# SYSCTL_1.0 register map
Vendor: Texas Instruments
Peripheral module from a debugger description file (folder mspm0gx51x).
Registers are 32-bit, read-write, no defined reset value unless marked. A register's access mark holds for its fields unless they carry their own. Offsets are as the file gives them; lines under a group give offsets from that group; [hi:lo] are bit positions; {n}, {i} and the like mark numbered series; 'fields as' and 'values as' point back to an identical list; <NAME> marks a mode.

## SYSCTL (part 1 of 2)
0x800 SYSCTL_MGMT_ADC12B4MSPS0_PWREN — IP Enable Register
  [0] ENABLE — IP Enable
    0=Disable; 1=Enable
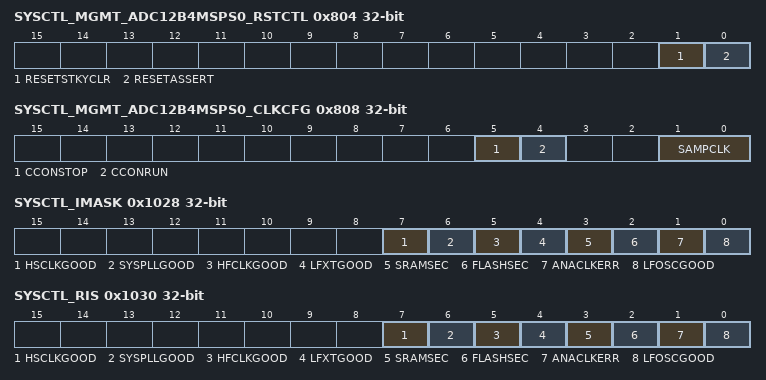
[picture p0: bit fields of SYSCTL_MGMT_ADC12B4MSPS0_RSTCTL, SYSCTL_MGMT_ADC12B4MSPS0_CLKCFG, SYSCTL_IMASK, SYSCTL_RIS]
0x804 SYSCTL_MGMT_ADC12B4MSPS0_RSTCTL — Power Control Register - Write Only Register, Always Read as 0
  [1] RESETSTKYCLR — Clear the RESET STICKY Bit
    1=Clear
  [0] RESETASSERT — Assert Reset to IP Domain.
    1=Do
0x808 SYSCTL_MGMT_ADC12B4MSPS0_CLKCFG — IP Clock Configuration Register
  [5] CCONSTOP — Conversion Clock is ON during STOP Mode
    0=Disable; 1=Enable
  [4] CCONRUN — Conversion Clock is ON during RUN Mode
    0=Disable; 1=Enable
  [1:0] SAMPCLK — Sample Window Clock
    0=ULPCLK; 1=SYSOSC; 2=HFCLK
0x814 SYSCTL_MGMT_ADC12B4MSPS0_STAT ro — IP State Register - Read Only
  [16] RESETSTKY — IP has been Reset
    0=clear; 1=Set
0x1020 SYSCTL_IIDX ro — SYSCTL interrupt index
  [3:0] STAT — The SYSCTL interrupt index (IIDX) register generates a value corresponding to the highest priority pending interrupt source. This value may be used as an address offset for fast, deterministic handling in the interrupt service routine. A read of the IIDX register will clear the corresponding interrupt status in the RIS and MIS registers.
    0=NO_INTR (No interrupt pending); 1=LFOSCGOOD (LFOSCGOOD interrupt pending); 2=ANACLKERR; 3=FLASHSEC; 4=SRAMSEC; 5=LFXTGOOD; 6=HFCLKGOOD; 7=SYSPLLGOOD; 8=HSCLKGOOD
0x1028 SYSCTL_IMASK — SYSCTL interrupt mask
  [7] HSCLKGOOD
    0=DISABLE; 1=ENABLE
  [6] SYSPLLGOOD
    0=DISABLE; 1=ENABLE
  [5] HFCLKGOOD
    0=DISABLE; 1=ENABLE
  [4] LFXTGOOD
    0=DISABLE; 1=ENABLE
  [3] SRAMSEC — SRAM Single Error Correct
    0=DISABLE; 1=ENABLE
  [2] FLASHSEC — Flash Single Error Correct
    0=DISABLE; 1=ENABLE
  [1] ANACLKERR — Analog Clocking Consistency Error
    0=DISABLE; 1=ENABLE
  [0] LFOSCGOOD — Enable or disable the LFOSCGOOD interrupt. LFOSCGOOD indicates that the LFOSC has started successfully.
    0=DISABLE (Interrupt disabled); 1=ENABLE (Interrupt enabled)
0x1030 SYSCTL_RIS ro — SYSCTL raw interrupt status
  [7] HSCLKGOOD
    0=FALSE; 1=TRUE
  [6] SYSPLLGOOD
    0=FALSE; 1=TRUE
  [5] HFCLKGOOD
    0=FALSE; 1=TRUE
  [4] LFXTGOOD
    0=FALSE; 1=TRUE
  [3] SRAMSEC — SRAM Single Error Correct
    0=FALSE; 1=TRUE
  [2] FLASHSEC — Flash Single Error Correct
    0=FALSE; 1=TRUE
  [1] ANACLKERR — Analog Clocking Consistency Error
    0=FALSE; 1=TRUE
  [0] LFOSCGOOD — Raw status of the LFOSCGOOD interrupt.
    0=FALSE (No interrupt pending); 1=TRUE (Interrupt pending)
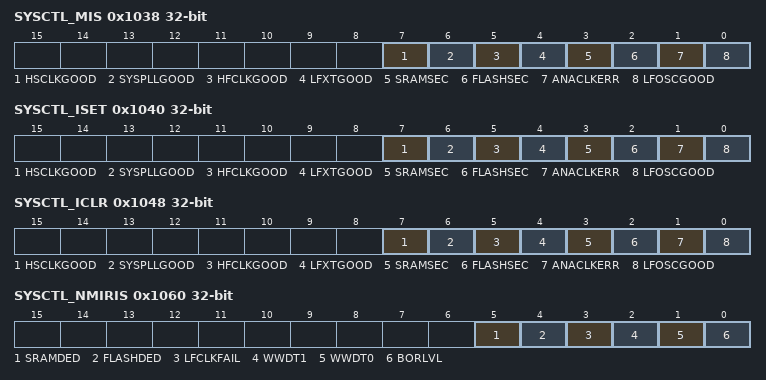
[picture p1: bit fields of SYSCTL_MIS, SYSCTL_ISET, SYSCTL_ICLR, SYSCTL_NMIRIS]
0x1038 SYSCTL_MIS ro — SYSCTL masked interrupt status
  [7] HSCLKGOOD
    0=FALSE; 1=TRUE
  [6] SYSPLLGOOD
    0=FALSE; 1=TRUE
  [5] HFCLKGOOD
    0=FALSE; 1=TRUE
  [4] LFXTGOOD
    0=FALSE; 1=TRUE
  [3] SRAMSEC — SRAM Single Error Correct
    0=FALSE; 1=TRUE
  [2] FLASHSEC — Flash Single Error Correct
    0=FALSE; 1=TRUE
  [1] ANACLKERR — Analog Clocking Consistency Error
    0=FALSE; 1=TRUE
  [0] LFOSCGOOD — Masked status of the LFOSCGOOD interrupt.
    0=FALSE (No interrupt pending); 1=TRUE (Interrupt pending)
0x1040 SYSCTL_ISET — SYSCTL interrupt set
  [7] HSCLKGOOD
    0=NO_EFFECT; 1=SET
  [6] SYSPLLGOOD
    0=NO_EFFECT; 1=SET
  [5] HFCLKGOOD
    0=NO_EFFECT; 1=SET
  [4] LFXTGOOD
    0=NO_EFFECT; 1=SET
  [3] SRAMSEC — SRAM Single Error Correct
    0=NO_EFFECT; 1=SET
  [2] FLASHSEC — Flash Single Error Correct
    0=NO_EFFECT; 1=SET
  [1] ANACLKERR — Analog Clocking Consistency Error
    0=NO_EFFECT; 1=SET
  [0] LFOSCGOOD — Set the LFOSCGOOD interrupt.
    0=NO_EFFECT (Writing 0h hs no effect); 1=SET (Set interrupt)
0x1048 SYSCTL_ICLR — SYSCTL interrupt clear
  [7] HSCLKGOOD
    0=NO_EFFECT; 1=CLR
  [6] SYSPLLGOOD
    0=NO_EFFECT; 1=CLR
  [5] HFCLKGOOD
    0=NO_EFFECT; 1=CLR
  [4] LFXTGOOD
    0=NO_EFFECT; 1=CLR
  [3] SRAMSEC — SRAM Single Error Correct
    0=NO_EFFECT; 1=CLR
  [2] FLASHSEC — Flash Single Error Correct
    0=NO_EFFECT; 1=CLR
  [1] ANACLKERR — Analog Clocking Consistency Error
    0=NO_EFFECT; 1=CLR
  [0] LFOSCGOOD — Clear the LFOSCGOOD interrupt.
    0=NO_EFFECT (Writing 0h has no effect); 1=CLR (Clear interrupt)
0x1050 SYSCTL_NMIIIDX ro — NMI interrupt index
  [3:0] STAT — The NMI interrupt index (NMIIIDX) register generates a value corresponding to the highest priority pending NMI source. This value may be used as an address offset for fast, deterministic handling in the NMI service routine. A read of the NMIIIDX register will clear the corresponding interrupt status in the NMIRIS register.
    0=NO_INTR (No NMI pending); 1=BORLVL (BOR Threshold NMI pending); 2=WWDT0; 3=WWDT1; 4=LFCLKFAIL; 5=FLASHDED; 6=SRAMDED
0x1060 SYSCTL_NMIRIS ro — NMI raw interrupt status
  [5] SRAMDED — SRAM Double Error Detect
    0=FALSE; 1=TRUE
  [4] FLASHDED — Flash Double Error Detect
    0=FALSE; 1=TRUE
  [3] LFCLKFAIL — LFXT-EXLF Monitor Fail
    0=FALSE; 1=TRUE
  [2] WWDT1 — Watch Dog 0 Fault
    0=FALSE; 1=TRUE
  [1] WWDT0 — Watch Dog 0 Fault
    0=FALSE; 1=TRUE
  [0] BORLVL — Raw status of the BORLVL NMI
    0=FALSE (No interrupt pending); 1=TRUE (Interrupt pending)
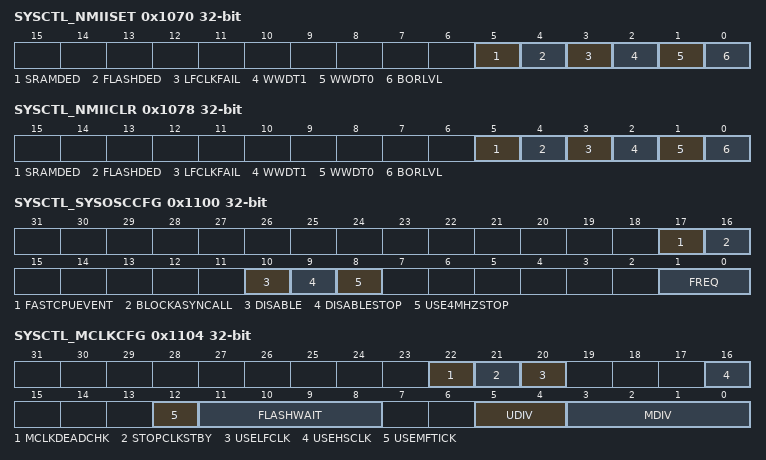
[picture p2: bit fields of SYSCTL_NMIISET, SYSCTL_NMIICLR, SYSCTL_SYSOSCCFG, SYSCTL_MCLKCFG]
0x1070 SYSCTL_NMIISET — NMI interrupt set
  [5] SRAMDED — SRAM Double Error Detect
    0=NO_EFFECT; 1=SET
  [4] FLASHDED — Flash Double Error Detect
    0=NO_EFFECT; 1=SET
  [3] LFCLKFAIL — LFXT-EXLF Monitor Fail
    0=NO_EFFECT; 1=SET
  [2] WWDT1 — Watch Dog 0 Fault
    0=NO_EFFECT; 1=SET
  [1] WWDT0 — Watch Dog 0 Fault
    0=NO_EFFECT; 1=SET
  [0] BORLVL — Set the BORLVL NMI
    0=NO_EFFECT (Writing 0h hs no effect); 1=SET (Set interrupt)
0x1078 SYSCTL_NMIICLR — NMI interrupt clear
  [5] SRAMDED — SRAM Double Error Detect
    0=NO_EFFECT; 1=CLR
  [4] FLASHDED — Flash Double Error Detect
    0=NO_EFFECT; 1=CLR
  [3] LFCLKFAIL — LFXT-EXLF Monitor Fail
    0=NO_EFFECT; 1=CLR
  [2] WWDT1 — Watch Dog 0 Fault
    0=NO_EFFECT; 1=CLR
  [1] WWDT0 — Watch Dog 0 Fault
    0=NO_EFFECT; 1=CLR
  [0] BORLVL — Clr the BORLVL NMI
    0=NO_EFFECT (Writing 0h hs no effect); 1=CLR (Clear interrupt)
0x1100 SYSCTL_SYSOSCCFG — SYSOSC configuration
  [17] FASTCPUEVENT — FASTCPUEVENT may be used to assert a fast clock request when an interrupt is asserted to the CPU, reducing interrupt latency.
    0=DISABLE (An interrupt to the CPU will not assert a fast clock request); 1=ENABLE (An interrupt to the CPU will assert a fast clock request)
  [16] BLOCKASYNCALL — BLOCKASYNCALL may be used to mask block all asynchronous fast clock requests, preventing hardware from dynamically changing the active clock configuration when operating in a given mode.
    0=DISABLE (Asynchronous fast clock requests are controlled by the requesting peripheral); 1=ENABLE (All asynchronous fast clock requests are blocked)
  [10] DISABLE — DISABLE sets the SYSOSC enable/disable policy. SYSOSC may be powered off in RUN, SLEEP, and STOP modes to reduce power consumption. When SYSOSC is disabled, MCLK and ULPCLK are sourced from LFCLK.
    0=DISABLE (Do not disable SYSOSC); 1=ENABLE (Disable SYSOSC immediately and source MCLK and ULPCLK from LFCLK)
  [9] DISABLESTOP — DISABLESTOP sets the SYSOSC stop mode enable/disable policy. When operating in STOP mode, the SYSOSC may be automatically disabled. When set, ULPCLK will run from LFCLK in STOP mode and SYSOSC will be disabled to reduce power consumption.
    0=DISABLE (Do not disable SYSOSC in STOP mode); 1=ENABLE (Disable SYSOSC in STOP mode and source ULPCLK from LFCLK)
  [8] USE4MHZSTOP — USE4MHZSTOP sets the SYSOSC stop mode frequency policy. When entering STOP mode, the SYSOSC frequency may be automatically switched to 4MHz to reduce SYSOSC power consumption.
    0=DISABLE (Do not gear shift the SYSOSC to 4MHz in STOP mode); 1=ENABLE (Gear shift SYSOSC to 4MHz in STOP mode)
  [1:0] FREQ — Target operating frequency for the system oscillator (SYSOSC)
    0=SYSOSCBASE (Base frequency (32MHz)); 1=SYSOSC4M (Low frequency (4MHz)); 2=SYSOSCUSER (User-trimmed frequency (16 or 24 MHz))
0x1104 SYSCTL_MCLKCFG — Main clock (MCLK) configuration
  [22] MCLKDEADCHK — MCLKDEADCHK enables or disables the continuous MCLK dead check monitor. LFCLK must be running before MCLKDEADCHK is enabled.
    0=DISABLE (The MCLK dead check monitor is disabled); 1=ENABLE (The MCLK dead check monitor is enabled)
  [21] STOPCLKSTBY — STOPCLKSTBY sets the STANDBY mode policy (STANDBY0 or STANDBY1). When set, ULPCLK and LFCLK are disabled to all peripherals in STANDBY mode, with the exception of TIMG0 and TIMG1 which continue to run. Wake-up is only possible via an asynchronous fast clock request.
    0=DISABLE (ULPCLK/LFCLK runs to all PD0 peripherals in STANDBY mode); 1=ENABLE (ULPCLK/LFCLK is disabled to all peripherals in STANDBY mode except TIMG0 and TIMG1)
  [20] USELFCLK — USELFCLK sets the MCLK source policy. Set USELFCLK to use LFCLK as the MCLK source. Note that setting USELFCLK does not disable SYSOSC, and SYSOSC remains available for direct use by analog modules.
    0=DISABLE (MCLK will not use the low frequency clock (LFCLK)); 1=ENABLE (MCLK will use the low frequency clock (LFCLK))
  [16] USEHSCLK — USEHSCLK, together with USELFCLK, sets the MCLK source policy. Set USEHSCLK to use HSCLK (HFCLK or SYSPLL) as the MCLK source in RUN and SLEEP modes.
    0=DISABLE (MCLK will not use the high speed clock (HSCLK)); 1=ENABLE (MCLK will use the high speed clock (HSCLK) in RUN and SLEEP mode)
  [12] USEMFTICK — USEMFTICK specifies whether the 4MHz constant-rate clock (MFCLK) to peripherals is enabled or disabled. When enabled, MDIV must be disabled (set to 0h=/1).
    0=DISABLE (The 4MHz rate MFCLK to peripherals is enabled); 1=ENABLE (The 4MHz rate MFCLK to peripherals is enabled.)
  [11:8] FLASHWAIT — FLASHWAIT specifies the number of flash wait states when MCLK is sourced from HSCLK. FLASHWAIT has no effect when MCLK is sourced from SYSOSC or LFCLK.
    0=WAIT0 (No flash wait states are applied); 1=WAIT1 (One flash wait state is applied); 2=WAIT2 (2 flash wait states are applied)
  [5:4] UDIV — UDIV specifies the ULPCLK divider when MCLK is sourced from HSCLK. UDIV has no effect when MCLK is sourced from SYSOSC or LFCLK.
    0=NODIVIDE (ULPCLK is not divided and is equal to MCLK); 1=DIVIDE2 (ULPCLK is MCLK/2 (divided-by-2))
  [3:0] MDIV — MDIV may be used to divide the MCLK frequency when MCLK is sourced from SYSOSC. MDIV=0h corresponds to /1 (no divider). MDIV=1h corresponds to /2 (divide-by-2). MDIV=Fh corresponds to /16 (divide-by-16). MDIV may be set between /1 and /16 on an integer basis.
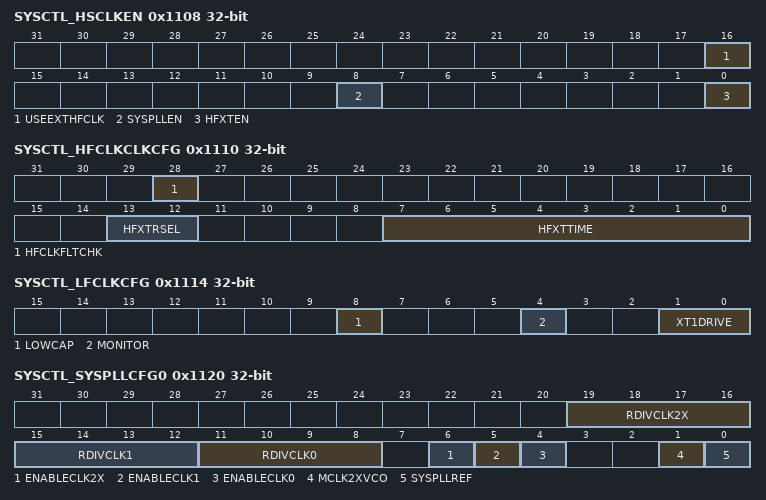
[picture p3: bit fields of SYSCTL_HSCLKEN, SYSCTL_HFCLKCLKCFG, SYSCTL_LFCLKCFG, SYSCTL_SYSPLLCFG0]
0x1108 SYSCTL_HSCLKEN — High-speed clock (HSCLK) source enable/disable
  [16] USEEXTHFCLK — USEEXTHFCLK selects the HFCLK_IN digital clock input to be the source for HFCLK. When disabled, HFXT is the HFCLK source and HFXTEN may be set. Do not set HFXTEN and USEEXTHFCLK simultaneously.
    0=DISABLE (Use HFXT as the HFCLK source); 1=ENABLE (Use the HFCLK_IN digital clock input as the HFCLK source)
  [8] SYSPLLEN — SYSPLLEN enables or disables the system phase-lock loop (SYSPLL).
    0=DISABLE (Disable the SYSPLL); 1=ENABLE (Enable the SYSPLL)
  [0] HFXTEN — HFXTEN enables or disables the high frequency crystal oscillator (HFXT).
    0=DISABLE (Disable the HFXT); 1=ENABLE (Enable the HFXT)
0x110C SYSCTL_HSCLKCFG — High-speed clock (HSCLK) source selection
  [0] HSCLKSEL — HSCLKSEL selects the HSCLK source (SYSPLL or HFCLK).
    0=SYSPLL (HSCLK is sourced from the SYSPLL); 1=HFCLKCLK (HSCLK is sourced from the HFCLK)
0x1110 SYSCTL_HFCLKCLKCFG — High-frequency clock (HFCLK) configuration
  [28] HFCLKFLTCHK — HFCLKFLTCHK enables or disables the HFCLK startup monitor.
    0=DISABLE (HFCLK startup is not checked); 1=ENABLE (HFCLK startup is checked)
  [13:12] HFXTRSEL — HFXT Range Select
    0=RANGE4TO8 (4MHz <= HFXT frequency <= 8MHz); 1=RANGE8TO16 (8MHz < HFXT frequency <= 16MHz); 2=RANGE16TO32 (16MHz < HFXT frequency <= 32MHz); 3=RANGE32TO48 (32MHz < HFXT frequency <= 48MHz)
  [7:0] HFXTTIME — HFXTTIME specifies the HFXT startup time in 64us resolution. If the HFCLK startup monitor is enabled (HFCLKFLTCHK), HFXT will be checked after this time expires.
    0=MINSTARTTIME (Minimum startup time (approximatly zero)); 255=MAXSTARTTIME (Maximum startup time (approximatly 16.32ms))
0x1114 SYSCTL_LFCLKCFG — Low frequency crystal oscillator (LFXT) configuration
  [8] LOWCAP — LOWCAP controls the low-power LFXT mode. When the LFXT load capacitance is less than 3pf, LOWCAP may be set for reduced power consumption.
    0=DISABLE (LFXT low capacitance mode is disabled); 1=ENABLE (LFXT low capacitance mode is enabled)
  [4] MONITOR — MONITOR enables or disables the LFCLK monitor, which continuously checks LFXT or LFCLK_IN for a clock stuck fault.
    0=DISABLE (Clock monitor is disabled); 1=ENABLE (Clock monitor is enabled)
  [1:0] XT1DRIVE — XT1DRIVE selects the low frequency crystal oscillator (LFXT) drive strength.
    0=LOWESTDRV (Lowest drive and current); 1=LOWERDRV (Lower drive and current); 2=HIGHERDRV (Higher drive and current); 3=HIGHESTDRV (Highest drive and current)
0x1120 SYSCTL_SYSPLLCFG0 — SYSPLL reference and output configuration
  [19:16] RDIVCLK2X — RDIVCLK2X sets the final divider for the SYSPLLCLK2X output.
    {v}=CLK2XDIV{v+1} (SYSPLLCLK1 is divided by {v+1}) (v=0..15)
  [15:12] RDIVCLK1 — RDIVCLK1 sets the final divider for the SYSPLLCLK1 output.
    0=CLK1DIV2 (SYSPLLCLK1 is divided by 2); 1=CLK1DIV4 (SYSPLLCLK1 is divided by 4); 2=CLK1DIV6 (SYSPLLCLK1 is divided by 6); 3=CLK1DIV8 (SYSPLLCLK1 is divided by 8); 4=CLK1DIV10 (SYSPLLCLK1 is divided by 10); 5=CLK1DIV12 (SYSPLLCLK1 is divided by 12); 6=CLK1DIV14 (SYSPLLCLK1 is divided by 14); 7=CLK1DIV16 (SYSPLLCLK1 is divided by 16); 8=CLK1DIV18 (SYSPLLCLK1 is divided by 18); 9=CLK1DIV20 (SYSPLLCLK1 is divided by 20); 10=CLK1DIV22 (SYSPLLCLK1 is divided by 22); 11=CLK1DIV24 (SYSPLLCLK1 is divided by 24); 12=CLK1DIV26 (SYSPLLCLK1 is divided by 26); 13=CLK1DIV28 (SYSPLLCLK1 is divided by 28); 14=CLK1DIV30 (SYSPLLCLK1 is divided by 30); 15=CLK1DIV32 (SYSPLLCLK1 is divided by 32)
  [11:8] RDIVCLK0 — RDIVCLK0 sets the final divider for the SYSPLLCLK0 output.
    0=CLK0DIV2 (SYSPLLCLK0 is divided by 2); 1=CLK0DIV4 (SYSPLLCLK0 is divided by 4); 2=CLK0DIV6 (SYSPLLCLK0 is divided by 6); 3=CLK0DIV8 (SYSPLLCLK0 is divided by 8); 4=CLK0DIV10 (SYSPLLCLK0 is divided by 10); 5=CLK0DIV12 (SYSPLLCLK0 is divided by 12); 6=CLK0DIV14 (SYSPLLCLK0 is divided by 14); 7=CLK0DIV16 (SYSPLLCLK0 is divided by 16); 8=CLK0DIV18 (SYSPLLCLK0 is divided by 18); 9=CLK0DIV20 (SYSPLLCLK0 is divided by 20); 10=CLK0DIV22 (SYSPLLCLK0 is divided by 22); 11=CLK0DIV24 (SYSPLLCLK0 is divided by 24); 12=CLK0DIV26 (SYSPLLCLK0 is divided by 26); 13=CLK0DIV28 (SYSPLLCLK0 is divided by 28); 14=CLK0DIV30 (SYSPLLCLK0 is divided by 30); 15=CLK0DIV32 (SYSPLLCLK0 is divided by 32)
  [6] ENABLECLK2X — ENABLECLK2X enables or disables the SYSPLLCLK2X output.
    0=DISABLE (SYSPLLCLK2X is disabled); 1=ENABLE (SYSPLLCLK2X is enabled)
  [5] ENABLECLK1 — ENABLECLK1 enables or disables the SYSPLLCLK1 output.
    0=DISABLE (SYSPLLCLK1 is disabled); 1=ENABLE (SYSPLLCLK1 is enabled)
  [4] ENABLECLK0 — ENABLECLK0 enables or disables the SYSPLLCLK0 output.
    0=DISABLE (SYSPLLCLK0 is disabled); 1=ENABLE (SYSPLLCLK0 is enabled)
  [1] MCLK2XVCO — MCLK2XVCO selects the SYSPLL output which is sent to the HSCLK mux for use by MCLK.
    0=DISABLE (The SYSPLLCLK0 output is sent to the HSCLK mux); 1=ENABLE (The SYSPLLCLK2X output is sent to the HSCLK mux)
  [0] SYSPLLREF — SYSPLLREF selects the system PLL (SYSPLL) reference clock source.
    0=SYSOSC (SYSPLL reference is SYSOSC); 1=HFCLK (SYSPLL reference is HFCLK)
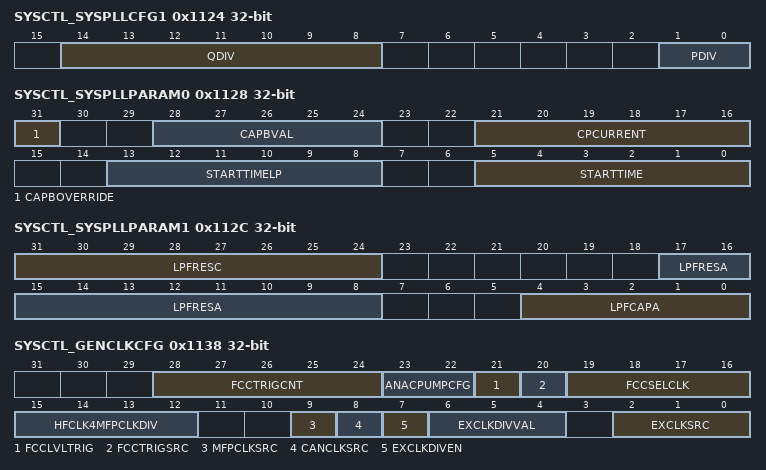
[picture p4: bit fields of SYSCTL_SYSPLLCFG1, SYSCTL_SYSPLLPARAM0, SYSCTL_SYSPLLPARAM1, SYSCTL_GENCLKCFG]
0x1124 SYSCTL_SYSPLLCFG1 — SYSPLL reference and feedback divider
  [14:8] QDIV — QDIV selects the SYSPLL feedback path divider.
    0=INVALID (Divide-by-one is not a valid QDIV option); 1=QDIVMIN (Feedback path is divided by 2); 126=QDIVMAX (Feedback path is divided by 127 (0x7E))
  [1:0] PDIV — PDIV selects the SYSPLL reference clock prescale divider.
    0=REFDIV1 (SYSPLLREF is not divided); 1=REFDIV2 (SYSPLLREF is divided by 2); 2=REFDIV4 (SYSPLLREF is divided by 4); 3=REFDIV8 (SYSPLLREF is divided by 8)
0x1128 SYSCTL_SYSPLLPARAM0 — SYSPLL PARAM0 (load from FACTORY region)
  [31] CAPBOVERRIDE — CAPBOVERRIDE controls the override for Cap B
    0=DISABLE (Cap B override disabled); 1=ENABLE (Cap B override enabled)
  [28:24] CAPBVAL — Override value for Cap B
  [21:16] CPCURRENT — Charge pump current
  [13:8] STARTTIMELP — Startup time from low power mode exit to locked clock, in 1us resolution
  [5:0] STARTTIME — Startup time from enable to locked clock, in 1us resolution
0x112C SYSCTL_SYSPLLPARAM1 — SYSPLL PARAM1 (load from FACTORY region)
  [31:24] LPFRESC — Loop filter Res C
  [17:8] LPFRESA — Loop filter Res A
  [4:0] LPFCAPA — Loop filter Cap A
0x1138 SYSCTL_GENCLKCFG — General clock configuration
  [28:24] FCCTRIGCNT — FCCTRIGCNT specifies the number of trigger clock periods in the trigger window. FCCTRIGCNT=0h (one trigger clock period) up to 1Fh (32 trigger clock periods) may be specified.
  [23:22] ANACPUMPCFG — ANACPUMPCFG selects the analog mux charge pump (VBOOST) enable method.
    0=ONDEMAND (VBOOST is enabled on request from a COMP, GPAMP, or OPA); 1=ONACTIVE (VBOOST is enabled when the device is in RUN or SLEEP mode, or when a COMP/GPAMP/OPA is enabled); 2=ONALWAYS (VBOOST is always enabled)
  [21] FCCLVLTRIG — FCCLVLTRIG selects the frequency clock counter (FCC) trigger mode.
    0=RISE2RISE (Rising edge to rising edge triggered); 1=LEVEL (Level triggered)
  [20] FCCTRIGSRC — FCCTRIGSRC selects the frequency clock counter (FCC) trigger source.
    0=EXTPIN (FCC trigger is the external pin); 1=LFCLK (FCC trigger is the LFCLK)
  [19:16] FCCSELCLK — FCCSELCLK selectes the frequency clock counter (FCC) clock source.
    0=MCLK (FCC clock is MCLK); 1=SYSOSC (FCC clock is SYSOSC); 2=HFCLK (FCC clock is HFCLK); 3=EXTCLK (FCC clock is the CLK_OUT selection); 4=SYSPLLCLK0 (FCC clock is SYSPLLCLK0); 5=SYSPLLCLK1 (FCC clock is SYSPLLCLK1); 6=SYSPLLCLK2X (FCC clock is SYSPLLCLK2X); 7=FCCIN (FCC clock is the FCCIN external input)
  [15:12] HFCLK4MFPCLKDIV — HFCLK4MFPCLKDIV selects the divider applied to HFCLK when HFCLK is used as the MFPCLK source. Integer dividers from /1 to /16 may be selected.
    0=DIV1 (HFCLK is not divided before being used for MFPCLK); {v}=DIV{v+1} (HFCLK is divided by {v+1} before being used for MFPCLK) (v=1..15)
  [9] MFPCLKSRC — MFPCLKSRC selects the MFPCLK (middle frequency precision clock) source.
    0=SYSOSC (MFPCLK is sourced from SYSOSC); 1=HFCLK (MFPCLK is sourced from HFCLK)
  [8] CANCLKSRC — CANCLKSRC selects the CANCLK source.
    0=HFCLK (CANCLK source is HFCLK); 1=SYSPLLOUT1 (CANCLK source is SYSPLLCLK1)
  [7] EXCLKDIVEN — EXCLKDIVEN enables or disables the divider function of the CLK_OUT external clock output block.
    0=PASSTHRU (CLock divider is disabled (passthrough, EXCLKDIVVAL is not applied)); 1=ENABLE (Clock divider is enabled (EXCLKDIVVAL is applied))
  [6:4] EXCLKDIVVAL — EXCLKDIVVAL selects the divider value for the divider in the CLK_OUT external clock output block.
    0=DIV2 (CLK_OUT source is divided by 2); 1=DIV4 (CLK_OUT source is divided by 4); 2=DIV6 (CLK_OUT source is divided by 6); 3=DIV8 (CLK_OUT source is divided by 8); 4=DIV10 (CLK_OUT source is divided by 10); 5=DIV12 (CLK_OUT source is divided by 12); 6=DIV14 (CLK_OUT source is divided by 14); 7=DIV16 (CLK_OUT source is divided by 16)
  [2:0] EXCLKSRC — EXCLKSRC selects the source for the CLK_OUT external clock output block. ULPCLK and MFPCLK require the CLK_OUT divider (EXCLKDIVEN) to be enabled
    0=SYSOSC (CLK_OUT is SYSOSC); 1=ULPCLK (CLK_OUT is ULPCLK (EXCLKDIVEN must be enabled)); 2=LFCLK (CLK_OUT is LFCLK); 3=MFPCLK (CLK_OUT is MFPCLK (EXCLKDIVEN must be enabled)); 4=HFCLK (CLK_OUT is HFCLK); 5=SYSPLLOUT1 (CLK_OUT is SYSPLLCLK1 (SYSPLLCLK1 must be <=48MHz))
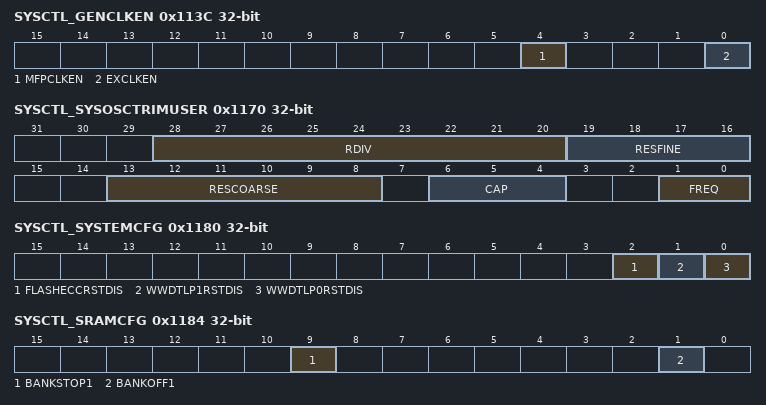
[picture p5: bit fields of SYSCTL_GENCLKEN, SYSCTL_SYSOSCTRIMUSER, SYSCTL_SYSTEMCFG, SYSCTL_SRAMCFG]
0x113C SYSCTL_GENCLKEN — General clock enable control
  [4] MFPCLKEN — MFPCLKEN enables the middle frequency precision clock (MFPCLK).
    0=DISABLE (MFPCLK is disabled); 1=ENABLE (MFPCLK is enabled)
  [0] EXCLKEN — EXCLKEN enables the CLK_OUT external clock output block.
    0=DISABLE (CLK_OUT block is disabled); 1=ENABLE (CLK_OUT block is enabled)
0x1140 SYSCTL_PMODECFG — Power mode configuration
  [1:0] DSLEEP — DSLEEP selects the operating mode to enter upon a DEEPSLEEP request from the CPU.
    0=STOP (STOP mode is entered); 1=STANDBY (STANDBY mode is entered); 2=SHUTDOWN (SHUTDOWN mode is entered)
0x1150 SYSCTL_FCC ro — Frequency clock counter (FCC) count
  [21:0] DATA — Frequency clock counter (FCC) count value.
0x1170 SYSCTL_SYSOSCTRIMUSER — SYSOSC user-specified trim
  [28:20] RDIV — RDIV specifies the frequency correction loop (FCL) resistor trim. This value changes with the target frequency.
  [19:16] RESFINE — RESFINE specifies the resister fine trim. This value changes with the target frequency.
  [13:8] RESCOARSE — RESCOARSE specifies the resister coarse trim. This value changes with the target frequency.
  [6:4] CAP — CAP specifies the SYSOSC capacitor trim. This value changes with the target frequency.
  [1:0] FREQ — FREQ specifies the target user-trimmed frequency for SYSOSC.
    1=SYSOSC16M (16MHz user frequency); 2=SYSOSC24M (24MHz user frequency)
0x1178 SYSCTL_SRAMBOUNDARY — SRAM Write Boundary
  [19:5] ADDR — SRAM boundary configuration. The value configured into this acts such that: SRAM accesses to addresses less than or equal value will be RW only. SRAM accesses to addresses greater than value will be RX only. Value of 0 is not valid (system will have no stack). If set to 0, the system acts as if the entire SRAM is RWX. Any non-zero value can be configured, including a value = SRAM size.
0x117C SYSCTL_SRAMBOUNDARYHIGH — SRAM Write Boundary High
  [19:5] ADDR — SRAM boundary high configuration. The value configured into this acts such that: SRAM accesses to greater than value will be RW only. SRAM accesses to addresses less than or equal to value will be RX until meeting SRAMBOUNDARY MMR Value. Value of 0 is default. If value set to less than or equal to SRAMBOUNDARY MMR, the system will only use the SRAMBOUNDARY MMR as criteria.
0x1180 SYSCTL_SYSTEMCFG — System configuration
  [2] FLASHECCRSTDIS — FLASHECCRSTDIS specifies whether a flash ECC double error detect (DED) will trigger a SYSRST or an NMI.
    0=FALSE (Flash ECC DED will trigger a SYSRST); 1=TRUE (Flash ECC DED will trigger a NMI)
  [1] WWDTLP1RSTDIS — WWDTLP1RSTDIS specifies whether a WWDT Error Event will trigger a SYSRST or an NMI.
    0=FALSE (WWDTLP1 Error Event will trigger a SYSRST); 1=TRUE (WWDTLP1 Error Event will trigger an NMI)
  [0] WWDTLP0RSTDIS — WWDTLP0RSTDIS specifies whether a WWDT Error Event will trigger a BOOTRST or an NMI.
    0=FALSE (WWDTLP0 Error Event will trigger a BOOTRST); 1=TRUE (WWDTLP0 Error Event will trigger an NMI)
0x1184 SYSCTL_SRAMCFG — System SRAM configuration
  [9] BANKSTOP1 — SRAM BANK1 power level for STOP mode
    0=FALSE (SRAM BANK1 power OFF for STOP mode); 1=TRUE (SRAM BANK1 power RETAIN for STOP mode)
  [1] BANKOFF1 — SRAM BANK1 power level for RUN mode
    0=FALSE (SRAM BANK1 power ON for RUN mode); 1=TRUE (SRAM BANK1 power OFF for RUN mode)
0x1200 SYSCTL_WRITELOCK — SYSCTL register write lockout
  [0] ACTIVE — ACTIVE controls whether critical SYSCTL registers are write protected or not.
    0=DISABLE (Allow writes to lockable registers); 1=ENABLE (Disallow writes to lockable registers)
